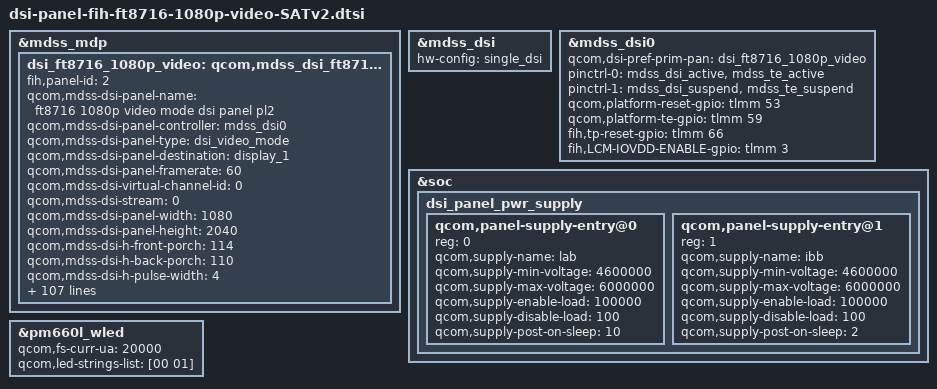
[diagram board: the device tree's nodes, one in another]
/* Copyright (c) 2013, The Linux Foundation. All rights reserved.
 *
 * This program is free software; you can redistribute it and/or modify
 * it under the terms of the GNU General Public License version 2 and
 * only version 2 as published by the Free Software Foundation.
 *
 * This program is distributed in the hope that it will be useful,
 * but WITHOUT ANY WARRANTY; without even the implied warranty of
 * MERCHANTABILITY or FITNESS FOR A PARTICULAR PURPOSE.  See the
 * GNU General Public License for more details.
 */

/*---------------------------------------------------------------------------
 * This file is autogenerated file using gcdb parser. Please do not edit it.
 * Update input XML file to add a new entry or update variable in this file
 * VERSION = "1.0"
 *---------------------------------------------------------------------------*/
&mdss_mdp {
	dsi_ft8716_1080p_video: qcom,mdss_dsi_ft8716_ffd_video_s2 {
		fih,panel-id = <2>;
		qcom,mdss-dsi-panel-name = "ft8716 1080p video mode dsi panel pl2";
		qcom,mdss-dsi-panel-controller = <&mdss_dsi0>;
		qcom,mdss-dsi-panel-type = "dsi_video_mode";
		qcom,mdss-dsi-panel-destination = "display_1";
		qcom,mdss-dsi-panel-framerate = <60>;
		qcom,mdss-dsi-virtual-channel-id = <0>;
		qcom,mdss-dsi-stream = <0>;
		qcom,mdss-dsi-panel-width = <1080>;
		qcom,mdss-dsi-panel-height = <2040>;
		qcom,mdss-dsi-h-front-porch = <114>;
		qcom,mdss-dsi-h-back-porch = <110>;
		qcom,mdss-dsi-h-pulse-width = <4>;
		qcom,mdss-dsi-h-sync-skew = <0>;
		qcom,mdss-dsi-v-back-porch = <16>;
		qcom,mdss-dsi-v-front-porch = <16>;
		qcom,mdss-dsi-v-pulse-width = <2>;
		qcom,mdss-dsi-h-left-border = <0>;
		qcom,mdss-dsi-h-right-border = <0>;
		qcom,mdss-dsi-v-top-border = <0>;
		qcom,mdss-dsi-v-bottom-border = <0>;
		qcom,mdss-dsi-bpp = <24>;
		qcom,mdss-dsi-underflow-color = <0xff>;
		qcom,mdss-dsi-border-color = <0>;
		qcom,mdss-dsi-on-command = [
                                29  00  00  00  00  00  04  ff  87  16  01 
                                29 00 00 00 00 00 02 00 80 
                                29 01 00 00 00 00 03 ff 87 16 
                                29 00 00 00 00 00 02 00 80 
29 01 00 00 00 00 0d d8 80 
81 82 83 85 87 89 8b 8b 8a 89 88 
29 00 00 00 00 00 02 00 90 
29 01 00 00 00 00 0d d8 00 
02 02 03 04 05 06 08 06 06 06 04 
29 00 00 00 00 00 02 00 a0 
29 01 00 00 00 00 0d d8 00 00 00 
00 80 81 81 81 00 01 02 04 
29 00 00 00 00 00 02 00 b0 
29 01 00 00 00 00 0d d8 00 00 80 80 81 81 82 83 85 87 87 89 
29 00 00 00 00 00 02 00 c0 
29 01 00 00 00 00 0d d8 85 8d 91 97 a2 ad b9 c3 cd d3 d3 d6 
29 00 00 00 00 00 02 00 d0 
29 01 00 00 00 00 0d d8 02 05 07 0a 0e 12 16 1b 1e 1e 1e 1f 
29 00 00 00 00 00 02 00 e0 
29 01 00 00 00 00 04 d8 fc fb e9 
29 00 00 00 00 00 02 00 c0 
29 01 00 00 00 00 02 d7 41 
29 01 00 00 00 00 02 00 a0 
29 01 00 00 00 00 02 d7 05 
29 00 00 00 00 00 02 00 a0 
29 01 00 00 00 00 0d d6 0f 0f 0f 0f 0f 0f 0f 0f 0f 0f 0f 0f 
29 00 00 00 00 00 02 00 b0 29 01 00 00 00 00 0d d6 80 80 cd cd cd cd cd cd cd cd cd cd 
29 00 00 00 00 00 02 00 c0 29 01 00 00 00 00 0d d6 80 80 b3 b3 b3 b3 b3 b3 b3 b3 b3 b3 
29 00 00 00 00 00 02 00 d0 29 01 00 00 00 00 0d d6 80 80 9a 9a 9a 9a 9a 9a 9a 9a 9a 9a 
29 00 00 00 00 00 02 00 01 29 00 00 00 00 00 02 c6 10 
29 00 00 00 00 00 02 00 00 
29 01 00 00 00 00 13 c8 90 78 56 34 33 33 33 33 33 33 43 44 43 44 44 44 44 54 
29 00 00 00 00 00 02 00 01 29 00 00 00 00 00 02 c6 11 
29 00 00 00 00 00 02 00 00 29 01 00 00 00 00 13 c8 90 78 56 34 33 33 22 33 33 43 44 44 43 44 44 44 44 54 
29 00 00 00 00 00 02 00 01 29 00 00 00 00 00 02 c6 12 
29 00 00 00 00 00 02 00 00 29 01 00 00 00 00 13 c8 e0 8c 56 33 33 33 33 33 33 33 23 22 33 43 44 44 44 44 
29 00 00 00 00 00 02 00 01 29 00 00 00 00 00 02 c6 00 
29 00 00 00 00 00 02 00 00 29 01 00 00 00 00 02 92 00 
29 00 00 00 00 00 02 00 00 29 01 00 00 00 00 02 94 c4 
29 00 00 00 00 00 02 00 00 29 01 00 00 00 00 02 91 80 
29 00 00 00 00 00 02 00 00 29 01 00 00 00 00 04 ff 00 00 00 
29 00 00 00 00 00 02 00 80 29 00 00 00 00 00 03 ff 00 00
15 01 00 00 0a 00 02 55 00
 05 01 00 00 78 00 02 11 00
 05 01 00 00 00 00 02 29 00
 05 01 00 00 0a 00 02 35 00 ];
		qcom,mdss-dsi-off-command = [
			05 01 00 00 0A 00 02 28 00 
			05 01 00 00 78 00 02 10 00
		];
		/*new 4.4.190*/
				qcom,mdss-dsi-panel-hdr-enabled;
		qcom,mdss-dsi-panel-hdr-color-primaries = <14880 15935 32435
			16555 14945 30910 7790 3415>;
		qcom,mdss-dsi-panel-peak-brightness = <5643000>;
		qcom,mdss-dsi-panel-blackness-level = <6134>;
		/*new 4.4.190*/
		qcom,suspend-ulps-enabled;
		qcom,mdss-dsi-on-command-state = "dsi_lp_mode";
                qcom,mdss-dsi-post-mode-switch-on-command-state = "dsi_lp_mode";
		qcom,mdss-dsi-off-command-state = "dsi_hs_mode";
		qcom,mdss-dsi-h-sync-pulse = <0>;
		qcom,mdss-dsi-traffic-mode = "non_burst_sync_event";
		qcom,mdss-dsi-bllp-eof-power-mode;
		qcom,mdss-dsi-bllp-power-mode;
		qcom,mdss-dsi-lane-0-state;
		qcom,mdss-dsi-lane-1-state;
		qcom,mdss-dsi-lane-2-state;
		qcom,mdss-dsi-lane-3-state;
		qcom,mdss-dsi-t-clk-post = <0x0d>;
		qcom,mdss-dsi-t-clk-pre = <0x2d>;
                qcom,mdss-dsi-reset-sequence = <1 10>, <0 10>, <1 10>;
		qcom,dynamic-mode-switch-enabled;
		qcom,dynamic-mode-switch-type = "dynamic-switch-immediate";
		qcom,video-to-cmd-mode-switch-commands =
			[23 00 00 00 00 00 02 b0 00
			29 00 00 00 00 00 02 b3 0c
			23 01 00 00 00 00 02 b0 03];
		qcom,cmd-to-video-mode-switch-commands =
			[23 00 00 00 00 00 02 b0 00
			29 00 00 00 00 00 02 b3 1c
23 01 00 00 00 00 02 b0 03];
cm,mdss-livedisplay-cabc-cmd = [15 01 00 00 00 00 02 55 00];
			cm,mdss-livedisplay-cabc-ui-value = <0x01>;
			cm,mdss-livedisplay-cabc-image-value = <0x02>;
			cm,mdss-livedisplay-cabc-video-value = <0x03>;
			cm,mdss-livedisplay-command-state = "dsi_hs_mode";

			cm,mdss-livedisplay-post-cmd = [05 01 00 00 00 00 02 29 00];
		cm,mdss-livedisplay-sre-weak-value = <0x50>;
		cm,mdss-livedisplay-sre-medium-value = <0x60>;
		cm,mdss-livedisplay-sre-strong-value = <0x70>;
		cm,mdss-livedisplay-aco-value = <0x80>;

		/*Add by ZZDC sunqiupeng for esd check START*/
		qcom,esd-check-enabled;
		qcom,mdss-dsi-panel-status-check-mode = "reg_read";
		qcom,mdss-dsi-panel-status-command = [06 01 00 01 00 00 01 0a
		06 01 00 01 00 00 01 0d
		06 01 00 01 00 00 01 ac];
		qcom,mdss-dsi-panel-status-command-state = "dsi_hs_mode";
		qcom,mdss-dsi-panel-status-value = <0x9c>,<0x00>,<0x00>;
		qcom,mdss-dsi-panel-on-check-value = <0x9c>,<0x00>,<0x00>;
		qcom,mdss-dsi-panel-status-read-length = <1>,<1>,<1>;
		qcom,mdss-dsi-panel-max-error-count = <3>;
		/*Add by ZZDC sunqiupeng for esd check END*/

		qcom,mdss-dsi-cabc-off-command = [
			15 01 00 00 05 00 02 55 00
		];
		qcom,mdss-dsi-cabc-ui-command = [
			15 01 00 00 05 00 02 55 01
		];
		qcom,mdss-dsi-cabc-still-command = [
			15 01 00 00 05 00 02 55 02
		];
		qcom,mdss-dsi-cabc-moving-command = [
			15 01 00 00 05 00 02 55 03
		];

		qcom,mdss-dsi-cabc-off-command-state = "dsi_hs_mode";
		qcom,mdss-dsi-cabc-ui-command-state = "dsi_hs_mode";
		qcom,mdss-dsi-cabc-still-command-state = "dsi_lp_mode";
		qcom,mdss-dsi-cabc-moving-command-state = "dsi_lp_mode";

		qcom,mdss-dsi-dma-trigger = "trigger_sw";
		qcom,mdss-dsi-mdp-trigger = "none";
	/*	qcom,mdss-dsi-reset-sequence = <1 2>, <0 5>, <1 10>; */

		qcom,mdss-pan-physical-width-dimension = <65>;
		qcom,mdss-pan-physical-height-dimension = <123>;
		qcom,mdss-pan-physical-width-dimension-full = <6504>;
		qcom,mdss-pan-physical-height-dimension-full = <12300>;
	};
};

&dsi_ft8716_1080p_video {
	qcom,mdss-dsi-panel-timings-phy-v2 = [23 1e 07 09 05 03 04 a0
		23 1e 07 09 05 03 04 a0
		23 1e 07 09 05 03 04 a0
		23 1e 07 09 05 03 04 a0
		23 19 07 08 05 03 04 a0];
	qcom,mdss-dsi-bl-pmic-control-type = "bl_ctrl_wled";
	qcom,mdss-dsi-bl-min-level = <1>;
	qcom,mdss-dsi-bl-max-level = <4095>;
	qcom,panel-supply-entries = <&dsi_panel_pwr_supply>;
	qcom,mdss-dsi-min-refresh-rate = <53>;
	qcom,mdss-dsi-max-refresh-rate = <70>;
	qcom,mdss-dsi-pan-enable-dynamic-fps;
        qcom,mdss-dsi-pan-fps-update = "dfps_immediate_porch_mode_vfp";
};

&mdss_dsi {
	hw-config = "single_dsi";
};

&mdss_dsi0 {
	qcom,dsi-pref-prim-pan = <&dsi_ft8716_1080p_video>;
	pinctrl-names = "mdss_default", "mdss_sleep";
	pinctrl-0 = <&mdss_dsi_active &mdss_te_active>;
	pinctrl-1 = <&mdss_dsi_suspend &mdss_te_suspend>;
	qcom,platform-reset-gpio = <&tlmm 53 0>;
	qcom,platform-te-gpio = <&tlmm 59 0>;
	fih,tp-reset-gpio = <&tlmm 66 0>;
	fih,LCM-IOVDD-ENABLE-gpio = <&tlmm 3 0>;
};

&soc {
	/delete-node/dsi_panel_pwr_supply;

	dsi_panel_pwr_supply: dsi_panel_pwr_supply {
		#address-cells = <1>;
		#size-cells = <0>;

		qcom,panel-supply-entry@0 {
			reg = <0>;
			qcom,supply-name = "lab";
			qcom,supply-min-voltage = <4600000>;
			qcom,supply-max-voltage = <6000000>;
			qcom,supply-enable-load = <100000>;
			qcom,supply-disable-load = <100>;
			qcom,supply-post-on-sleep = <10>;
		};

		qcom,panel-supply-entry@1 {
			reg = <1>;
			qcom,supply-name = "ibb";
			qcom,supply-min-voltage = <4600000>;
			qcom,supply-max-voltage = <6000000>;
			qcom,supply-enable-load = <100000>;
			qcom,supply-disable-load = <100>;
			qcom,supply-post-on-sleep = <2>;
		};
	};
};

//&msm_ext_disp {
//	status = "disabled";
//};

//&mdss_dp_ctrl {
//	status = "disabled";
//};

&pm660l_wled {
	qcom,fs-curr-ua = <20000>;
	qcom,led-strings-list = [00 01];
};
